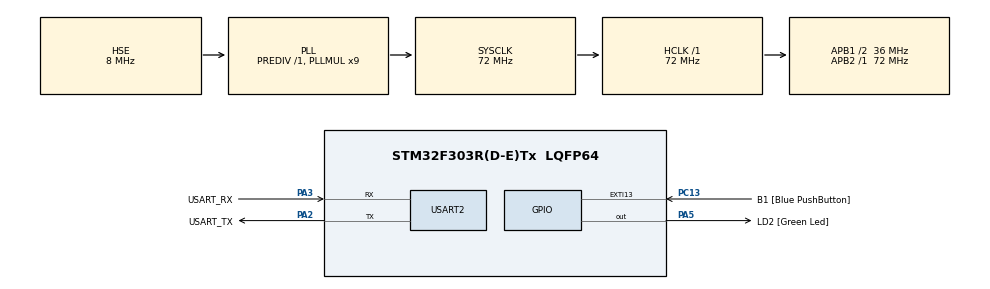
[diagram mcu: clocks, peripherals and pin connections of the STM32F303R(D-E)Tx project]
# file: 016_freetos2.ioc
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Mcu.Family=STM32F3
RCC.PLLSourceVirtual=RCC_PLLSOURCE_HSE
PC15-OSC32_OUT.Mode=LSE-External-Oscillator
PA2.GPIO_PuPd=GPIO_NOPULL
RCC.CortexFreq_Value=72000000
FREERTOS.Tasks01=defaultTask,0,128,StartDefaultTask,Default,NULL,Dynamic,NULL,NULL;myTask02,0,128,StartTask02,Default,NULL,Dynamic,NULL,NULL
PC13.Signal=GPXTI13
FREERTOS.INCLUDE_vTaskDelayUntil=1
PA14.GPIO_Label=TCK
RCC.SYSCLKSourceVirtual=RCC_SYSCLKSOURCE_PLLCLK
PA3.GPIO_PuPd=GPIO_NOPULL
PA2.GPIO_Speed=GPIO_SPEED_FREQ_LOW
PC13.GPIO_Label=B1 [Blue PushButton]
RCC.APB1CLKDivider=RCC_HCLK_DIV2
PC14-OSC32_IN.Signal=RCC_OSC32_IN
PA3.GPIO_Speed=GPIO_SPEED_FREQ_LOW
ProjectManager.StackSize=0x400
PA13.Signal=SYS_JTMS-SWDIO
PA3.Mode=Asynchronous
ProjectManager.TargetToolchain=STM32CubeIDE
PA3.GPIO_Mode=GPIO_MODE_AF_PP
RCC.HCLKFreq_Value=72000000
RCC.APB2TimFreq_Value=72000000
RCC.USBFreq_Value=72000000
PC15-OSC32_OUT.Signal=RCC_OSC32_OUT
RCC.AHBFreq_Value=72000000
PF0-OSC_IN.Mode=HSE-External-Oscillator
PA5.Signal=GPIO_Output
RCC.HSE_VALUE=8000000
board=NUCLEO-F303RE
USART2.VirtualMode-Asynchronous=VM_ASYNC
RCC.RCC_PLLsource_Clock_Source_FROM_HSE=RCC_HSE_PREDIV_DIV2
RCC.PLLMUL=RCC_PLL_MUL9
RCC.APB2Freq_Value=72000000
PC14-OSC32_IN.Mode=LSE-External-Oscillator
VP_SYS_VS_tim1.Mode=TIM1
PA5.GPIO_PuPd=GPIO_NOPULL
VP_FREERTOS_VS_CMSIS_V1.Mode=CMSIS_V1
Mcu.Name=STM32F303R(D-E)Tx
PA2.Signal=USART2_TX
PA13.GPIO_Label=TMS
PB3.Signal=SYS_JTDO-TRACESWO
RCC.SYSCLKFreq_VALUE=72000000
Mcu.Package=LQFP64
NVIC.TimeBase=TIM1_UP_TIM16_IRQn
PA5.GPIO_Label=LD2 [Green Led]
PC13.GPIO_ModeDefaultEXTI=GPIO_MODE_IT_FALLING
PA2.GPIO_Label=USART_TX
NVIC.TimeBaseIP=TIM1
PA14.Signal=SYS_JTCK-SWCLK
ProjectManager.HeapSize=0x200
RCC.HSI_VALUE=8000000
NVIC.TIM1_UP_TIM16_IRQn=true\:0\:0\:false\:false\:true\:false\:false\:true
RCC.PLLP=RCC_PLLP_DIV4
PA5.GPIO_Speed=GPIO_SPEED_FREQ_LOW
RCC.PLLQ=7
NVIC.PriorityGroup=NVIC_PRIORITYGROUP_4
RCC.PLLM=8
RCC.PLLN=336
RCC.APB1TimFreq_Value=72000000
PA2.Mode=Asynchronous
PF0-OSC_IN.Signal=RCC_OSC_IN
PF1-OSC_OUT.Mode=HSE-External-Oscillator
RCC.APB1Freq_Value=36000000
PA5.GPIO_Mode=GPIO_MODE_OUTPUT_PP
PF1-OSC_OUT.Signal=RCC_OSC_OUT
PA3.GPIO_Label=USART_RX
PA3.Signal=USART2_RX
PA2.GPIO_Mode=GPIO_MODE_AF_PP
PB3.GPIO_Label=SWO

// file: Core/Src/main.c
/* USER CODE BEGIN Header */
/**
  ******************************************************************************
  * @file           : main.c
  * @brief          : Main program body
  ******************************************************************************
  * @attention
  *
  * <h2><center>&copy; Copyright (c) 2021 STMicroelectronics.
  * All rights reserved.</center></h2>
  *
  * This software component is licensed by ST under BSD 3-Clause license,
  * the "License"; You may not use this file except in compliance with the
  * License. You may obtain a copy of the License at:
  *                        opensource.org/licenses/BSD-3-Clause
  *
  ******************************************************************************
  */
/* USER CODE END Header */
#include "main.h"
#include "cmsis_os.h"

/* USER CODE BEGIN Includes */
#include <stdio.h>
/* USER CODE END Includes */

UART_HandleTypeDef huart2;

osThreadId defaultTaskHandle;
osThreadId myTask02Handle;

void SystemClock_Config(void);
static void MX_GPIO_Init(void);
static void MX_USART2_UART_Init(void);
void StartDefaultTask(void const * argument);
void StartTask02(void const * argument);

/* USER CODE BEGIN 0 */
uint8_t indx=0;
/* USER CODE END 0 */

int main(void)
{

  /* MCU Configuration--------------------------------------------------------*/

  /* Reset of all peripherals, Initializes the Flash interface and the Systick. */
  HAL_Init();

  /* Configure the system clock */
  SystemClock_Config();

  /* Initialize all configured peripherals */
  MX_GPIO_Init();
  MX_USART2_UART_Init();

  /* Create the thread(s) */
  /* definition and creation of defaultTask */
  osThreadDef(defaultTask, StartDefaultTask, osPriorityNormal, 0, 128);
  defaultTaskHandle = osThreadCreate(osThread(defaultTask), NULL);

  /* definition and creation of myTask02 */
  osThreadDef(myTask02, StartTask02, osPriorityNormal, 0, 128);
  myTask02Handle = osThreadCreate(osThread(myTask02), NULL);

  /* Start scheduler */
  osKernelStart();

  /* We should never get here as control is now taken by the scheduler */
  /* Infinite loop */
  while (1)
  {

  }
}

void SystemClock_Config(void)
{
  RCC_OscInitTypeDef RCC_OscInitStruct = {0};
  RCC_ClkInitTypeDef RCC_ClkInitStruct = {0};
  RCC_PeriphCLKInitTypeDef PeriphClkInit = {0};

  /** Initializes the RCC Oscillators according to the specified parameters
  * in the RCC_OscInitTypeDef structure.
  */
  RCC_OscInitStruct.OscillatorType = RCC_OSCILLATORTYPE_HSE;
  RCC_OscInitStruct.HSEState = RCC_HSE_ON;
  RCC_OscInitStruct.HSIState = RCC_HSI_ON;
  RCC_OscInitStruct.PLL.PLLState = RCC_PLL_ON;
  RCC_OscInitStruct.PLL.PLLSource = RCC_PLLSOURCE_HSE;
  RCC_OscInitStruct.PLL.PLLMUL = RCC_PLL_MUL9;
  RCC_OscInitStruct.PLL.PREDIV = RCC_PREDIV_DIV1;
  if (HAL_RCC_OscConfig(&RCC_OscInitStruct) != HAL_OK)
  {
    Error_Handler();
  }
  /** Initializes the CPU, AHB and APB buses clocks
  */
  RCC_ClkInitStruct.ClockType = RCC_CLOCKTYPE_HCLK|RCC_CLOCKTYPE_SYSCLK
                              |RCC_CLOCKTYPE_PCLK1|RCC_CLOCKTYPE_PCLK2;
  RCC_ClkInitStruct.SYSCLKSource = RCC_SYSCLKSOURCE_PLLCLK;
  RCC_ClkInitStruct.AHBCLKDivider = RCC_SYSCLK_DIV1;
  RCC_ClkInitStruct.APB1CLKDivider = RCC_HCLK_DIV2;
  RCC_ClkInitStruct.APB2CLKDivider = RCC_HCLK_DIV1;

  if (HAL_RCC_ClockConfig(&RCC_ClkInitStruct, FLASH_LATENCY_2) != HAL_OK)
  {
    Error_Handler();
  }
  PeriphClkInit.PeriphClockSelection = RCC_PERIPHCLK_USART2;
  PeriphClkInit.Usart2ClockSelection = RCC_USART2CLKSOURCE_PCLK1;
  if (HAL_RCCEx_PeriphCLKConfig(&PeriphClkInit) != HAL_OK)
  {
    Error_Handler();
  }
}

static void MX_USART2_UART_Init(void)
{

  huart2.Instance = USART2;
  huart2.Init.BaudRate = 38400;
  huart2.Init.WordLength = UART_WORDLENGTH_8B;
  huart2.Init.StopBits = UART_STOPBITS_1;
  huart2.Init.Parity = UART_PARITY_NONE;
  huart2.Init.Mode = UART_MODE_TX_RX;
  huart2.Init.HwFlowCtl = UART_HWCONTROL_NONE;
  huart2.Init.OverSampling = UART_OVERSAMPLING_16;
  huart2.Init.OneBitSampling = UART_ONE_BIT_SAMPLE_DISABLE;
  huart2.AdvancedInit.AdvFeatureInit = UART_ADVFEATURE_NO_INIT;
  if (HAL_UART_Init(&huart2) != HAL_OK)
  {
    Error_Handler();
  }

}

static void MX_GPIO_Init(void)
{
  GPIO_InitTypeDef GPIO_InitStruct = {0};

  /* GPIO Ports Clock Enable */
  __HAL_RCC_GPIOC_CLK_ENABLE();
  __HAL_RCC_GPIOF_CLK_ENABLE();
  __HAL_RCC_GPIOA_CLK_ENABLE();
  __HAL_RCC_GPIOB_CLK_ENABLE();

  /*Configure GPIO pin Output Level */
  HAL_GPIO_WritePin(LD2_GPIO_Port, LD2_Pin, GPIO_PIN_RESET);

  /*Configure GPIO pin : B1_Pin */
  GPIO_InitStruct.Pin = B1_Pin;
  GPIO_InitStruct.Mode = GPIO_MODE_IT_FALLING;
  GPIO_InitStruct.Pull = GPIO_NOPULL;
  HAL_GPIO_Init(B1_GPIO_Port, &GPIO_InitStruct);

  /*Configure GPIO pin : LD2_Pin */
  GPIO_InitStruct.Pin = LD2_Pin;
  GPIO_InitStruct.Mode = GPIO_MODE_OUTPUT_PP;
  GPIO_InitStruct.Pull = GPIO_NOPULL;
  GPIO_InitStruct.Speed = GPIO_SPEED_FREQ_LOW;
  HAL_GPIO_Init(LD2_GPIO_Port, &GPIO_InitStruct);

}

void StartDefaultTask(void const * argument)
{
  /* USER CODE BEGIN 5 */
  /* Infinite loop */
  for(;;)
  {
	printf ("default\n");
    osDelay(2000);
  }
  /* USER CODE END 5 */
}

void StartTask02(void const * argument)
{
  /* USER CODE BEGIN StartTask02 */
  /* Infinite loop */
  for(;;)
  {
		printf ("Task2 = %d\n", indx++);
	     osDelay(2000);

		if (indx==4)
		{
	           printf ("suspending DefaultTask\n");
                 osThreadSuspend(defaultTaskHandle);

		}
		if (indx ==7)
		{
		   printf ("Resuming DefaultTask\n");
		   osThreadResume(defaultTaskHandle);
	        }
    osDelay(1);
  }
  /* USER CODE END StartTask02 */
}

 /**
  * @brief  Period elapsed callback in non blocking mode
  * @note   This function is called  when TIM1 interrupt took place, inside
  * HAL_TIM_IRQHandler(). It makes a direct call to HAL_IncTick() to increment
  * a global variable "uwTick" used as application time base.
  * @param  htim : TIM handle
  * @retval None
  */
void HAL_TIM_PeriodElapsedCallback(TIM_HandleTypeDef *htim)
{
  if (htim->Instance == TIM1) {
    HAL_IncTick();
  }
}

void Error_Handler(void)
{
  __disable_irq();
  while (1)
  {
  }
}

/************************ (C) COPYRIGHT STMicroelectronics *****END OF FILE****/
